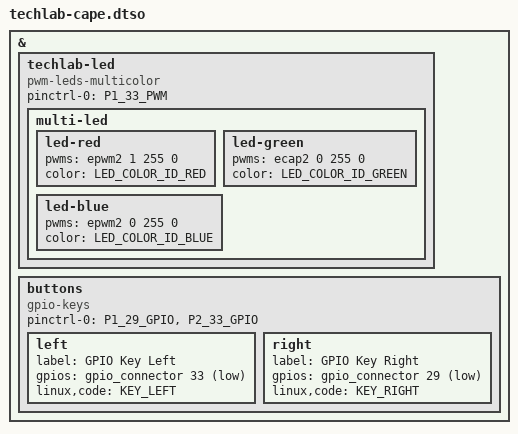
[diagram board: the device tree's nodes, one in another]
// SPDX-License-Identifier: GPL-2.0-only OR MIT
/*
 * Copyright (C) 2025 Ayush Singh, BeagleBoard.org Foundation
 */

/dts-v1/;
/plugin/;

#include <dt-bindings/leds/common.h>
#include <dt-bindings/gpio/gpio.h>
#include <dt-bindings/input/input.h>

/ {
	fragment@0 {
		target-path="";

		__overlay__ {
			techlab-led {
				status = "okay";
				compatible = "pwm-leds-multicolor";
				pinctrl-names = "default";
				pinctrl-0 = <&P1_33_PWM>;

				multi-led {
					led-red {
						pwms = <&epwm2 1 255 0>;
						color = <LED_COLOR_ID_RED>;
					};

					led-green {
						pwms = <&ecap2 0 255 0>;
						color = <LED_COLOR_ID_GREEN>;
					};

					led-blue {
						pwms = <&epwm2 0 255 0>;
						color = <LED_COLOR_ID_BLUE>;
					};
				};
			};

			buttons {
				compatible = "gpio-keys";
				pinctrl-names = "default";
				pinctrl-0 = <&P1_29_GPIO &P2_33_GPIO>;

				left {
					label = "GPIO Key Left";
					gpios = <&gpio_connector 33 GPIO_ACTIVE_LOW>;
        				linux,code = <KEY_LEFT>;
				};

				right {
					label = "GPIO Key Right";
					gpios = <&gpio_connector 29 GPIO_ACTIVE_LOW>;
        				linux,code = <KEY_RIGHT>;
				};
			};
		};
	};
};
